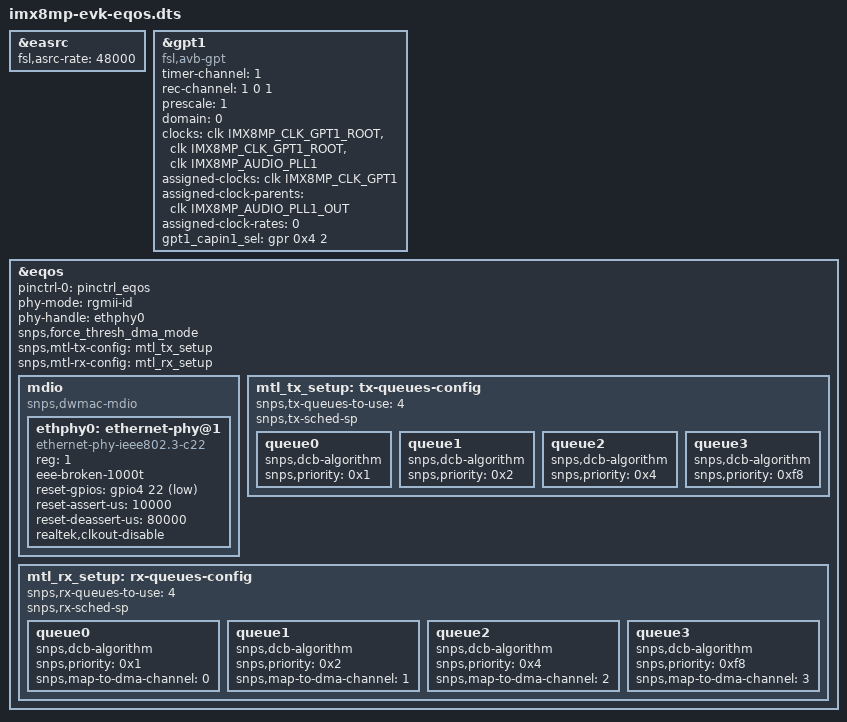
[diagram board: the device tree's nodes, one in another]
// SPDX-License-Identifier: (GPL-2.0+ OR MIT)
/*
 * Copyright 2021 NXP
 */

/dts-v1/;

#include "imx8mp-evk.dts"

/* Enable easrc */
&easrc {
	fsl,asrc-rate  = <48000>;
	status = "okay";
};

/* AVB HW timer*/
&gpt1 {
	compatible = "fsl,avb-gpt";
	timer-channel = <1>; /* Use output compare channel 1*/
	rec-channel = <1 0 1>; // capture channel, eth port, ENET TC id
	prescale = <1>;
	domain = <0>;

	clocks = <&clk IMX8MP_CLK_GPT1_ROOT>,
		 <&clk IMX8MP_CLK_GPT1_ROOT>,
		 <&clk IMX8MP_AUDIO_PLL1>;
	clock-names = "ipg", "per", "audio_pll";

	/* Make the GPT clk root derive from the audio PLL*/
	assigned-clocks = <&clk IMX8MP_CLK_GPT1>;
	assigned-clock-parents = <&clk IMX8MP_AUDIO_PLL1_OUT>;
	assigned-clock-rates = <0>;

	gpt1_capin1_sel = <&gpr 0x4 2>;

	status = "okay";
};

&eqos {
	pinctrl-names = "default";
	pinctrl-0 = <&pinctrl_eqos>;
	phy-mode = "rgmii-id";
	phy-handle = <&ethphy0>;
	snps,force_thresh_dma_mode;
	snps,mtl-tx-config = <&mtl_tx_setup>;
	snps,mtl-rx-config = <&mtl_rx_setup>;
	status = "okay";

	mdio {
		compatible = "snps,dwmac-mdio";
		#address-cells = <1>;
		#size-cells = <0>;

		ethphy0: ethernet-phy@1 {
			compatible = "ethernet-phy-ieee802.3-c22";
			reg = <1>;
			eee-broken-1000t;
			reset-gpios = <&gpio4 22 GPIO_ACTIVE_LOW>;
			reset-assert-us = <10000>;
			reset-deassert-us = <80000>;
			realtek,clkout-disable;
		};
	};

	mtl_tx_setup: tx-queues-config {
		snps,tx-queues-to-use = <4>;
		snps,tx-sched-sp;

		queue0 {
			snps,dcb-algorithm;
			snps,priority = <0x1>;
		};

		queue1 {
			snps,dcb-algorithm;
			snps,priority = <0x2>;
		};

		queue2 {
			snps,dcb-algorithm;
			snps,priority = <0x4>;
		};

		queue3 {
			snps,dcb-algorithm;
			snps,priority = <0xf8>;
		};
	};

	mtl_rx_setup: rx-queues-config {
		snps,rx-queues-to-use = <4>;
		snps,rx-sched-sp;

		queue0 {
			snps,dcb-algorithm;
			snps,priority = <0x1>;
			snps,map-to-dma-channel = <0>;
		};

		queue1 {
			snps,dcb-algorithm;
			snps,priority = <0x2>;
			snps,map-to-dma-channel = <1>;
		};

		queue2 {
			snps,dcb-algorithm;
			snps,priority = <0x4>;
			snps,map-to-dma-channel = <2>;
		};

		queue3 {
			snps,dcb-algorithm;
			snps,priority = <0xf8>;
			snps,map-to-dma-channel = <3>;
		};
	};
};
